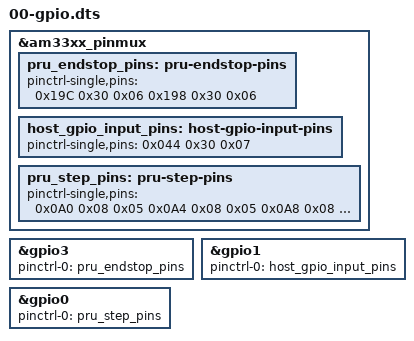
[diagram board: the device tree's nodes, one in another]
/* pickup-winder-00-gpio.dts
 * Centralise toutes les déclarations pinmux GPIO du projet PickupWinder.
 * Remplace 00-pru-steppers-endstops.dts et le fragment &gpio1 de 02-host_IO.dts.
 *
 * Targets BeagleBone Black - Kernel 6.12+ (Debian 12)
 * 3-cell format: <offset config_flags mux_mode>
 *
 * Bank mapping:
 *   GPIO3 bank : P9_28 (ENDSTOP_1, PRU0 R31[6])   ← PRU0 orchestrateur
 *                P9_30 (ENDSTOP_2, PRU0 R31[2])   ← PRU0 orchestrateur
 *
 *   GPIO1 bank : P9_23 (footswitch input, GPIO1[17])
 *
 *   GPIO0 bank : P8_45 (STEP_A, PRU1 R30[0])
 *                P8_46 (STEP_B, PRU1 R30[1])
 *                P8_43 (DIR_A,  PRU1 R30[2])
 *                P8_44 (DIR_B,  PRU1 R30[3])
 *                P8_41 (EN_A,   PRU1 R30[4], active-low)
 *                P8_42 (EN_B,   PRU1 R30[5], active-low)
 *
 * Note: bone-pinmux-helper absent sur kernel 6.12 → pinmux attaché via &gpioN.
 * Chaque groupe est attaché au contrôleur GPIO propriétaire des pads.
 */

/dts-v1/;
/plugin/;

&am33xx_pinmux {

    /* ── GPIO3 : entrées endstop PRU0 (P9_28 / P9_30) ──────────────────
     * P9_28 = conf_mcasp0_ahclkr  offset 0x19C  MODE6 = PRU0 R31[6] input
     * P9_30 = conf_mcasp0_axr0    offset 0x198  MODE6 = PRU0 R31[2] input
     * pull-up activé (0x30) : protège si le câble capteur est déconnecté  */
    pru_endstop_pins: pru-endstop-pins {
        pinctrl-single,pins = <
            0x19C 0x30 0x06  /* P9_28 ENDSTOP_1 (PRU0 R31[6]) rx-en, pull-up, MODE6 */
            0x198 0x30 0x06  /* P9_30 ENDSTOP_2 (PRU0 R31[2]) rx-en, pull-up, MODE6 */
        >;
    };

    /* ── GPIO1 : entrée host footswitch (P9_23, GPIO1[17], offset 0x044) ─
     * MODE7 = GPIO, pull-up interne activé                                */
    host_gpio_input_pins: host-gpio-input-pins {
        pinctrl-single,pins = <
            0x044 0x30 0x07  /* P9_23 footswitch : rx-en, pull-up, GPIO mode */
        >;
    };

    /* ── GPIO0 : sorties stepper PRU1 (P8_41..P8_46) ────────────────────
     * MODE5 = PRU1 R30 direct OUTPUT  (MODE6 = PRU1 R31 INPUT — ne pas confondre)
     * AM335x GPMC pins: MODE5 → pr1_pru1_pru_r30_N (output)
     *                   MODE6 → pr1_pru1_pru_r31_N (input)  ← MAUVAIS pour sorties
     *
     * Bits R30 réels (confirmés par pinctrl debugfs) :
     *   P8_45 → R30[0]  STEP_A
     *   P8_46 → R30[1]  STEP_B
     *   P8_43 → R30[2]  DIR_A
     *   P8_44 → R30[3]  DIR_B
     *   P8_41 → R30[4]  EN_A   (active-low)
     *   P8_42 → R30[5]  EN_B   (active-low)
     *
     * EN_A/EN_B : pull-up (active-low, état safe = driver désactivé si PRU OFF)
     * STEP/DIR : pull désactivé (piloté directement par PRU1)           */
    pru_step_pins: pru-step-pins {
        pinctrl-single,pins = <
            0x0A0 0x08 0x05  /* P8_45 STEP_A (PRU1 R30[0]) no pull,             MODE5=R30 out */
            0x0A4 0x08 0x05  /* P8_46 STEP_B (PRU1 R30[1]) no pull,             MODE5=R30 out */
            0x0A8 0x08 0x05  /* P8_43 DIR_A  (PRU1 R30[2]) no pull,             MODE5=R30 out */
            0x0AC 0x08 0x05  /* P8_44 DIR_B  (PRU1 R30[3]) no pull,             MODE5=R30 out */
            0x0B0 0x10 0x05  /* P8_41 EN_A   (PRU1 R30[4]) pull-up, active-low, MODE5=R30 out */
            0x0B4 0x10 0x05  /* P8_42 EN_B   (PRU1 R30[5]) pull-up, active-low, MODE5=R30 out */
        >;
    };
};

/* ── Attache GPIO3 : endstops PRU0 (P9_28 / P9_30) ─────────────────────
 * P9_28 et P9_30 appartiennent au bank GPIO3.
 * Muxés en MODE6 (PRU0 R31 input) — lus par l'orchestrateur PRU0.         */
&gpio3 {
    pinctrl-names = "default";
    pinctrl-0 = <&pru_endstop_pins>;
};

/* ── Attache GPIO1 : footswitch host (P9_23) ─────────────────────────────
 * P9_23 appartient au bank GPIO1 (GPIO1[17]).                              */
&gpio1 {
    pinctrl-names = "default";
    pinctrl-0 = <&host_gpio_input_pins>;
};

/* ── Attache GPIO0 : sorties stepper PRU1 (P8_41..P8_46) ───────────────
 * Ces pins appartiennent au bank GPIO0. */
&gpio0 {
    pinctrl-names = "default";
    pinctrl-0 = <&pru_step_pins>;
};
